# MSP430FR5962 register map
File version: 2.1
CPU: MSP430FR5962 r2p1, little endian, MPU, no FPU, 3 interrupt priority bits
Registers are 16-bit, read-write, reset 0x0 unless marked. A register's access mark holds for its fields unless they carry their own. Offsets are from the block's base; [hi:lo] are bit positions; 'fields as' and 'values as' point back to an identical list.

## RAMCTL
Base 0x00000158
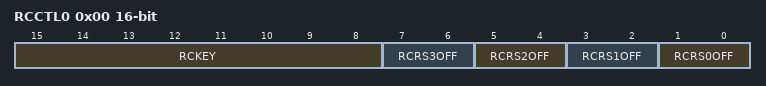
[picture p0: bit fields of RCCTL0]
0x00 RCCTL0 — RAM Controller Control 0
  [15:8] RCKEY — [15:8] RAM controller key. Always reads as 69h. Must be written as 5Ah; any other write is is ignored.
  [7:6] RCRS3OFF — [7:6] RAM controller RAM sector 3 off
    0=RCRS0OFF_0 (Contents of this RAM sector are retained in LPM3 and LPM4.); 1=RCRS0OFF_1 (Turns off this RAM sector in LPM3 and LPM4, re-activates it on wake-up. All data of this RAM sector is lost after wakeup from LPM3 and LPM4. See the device-specific data sheet to find the number of available sectors, the address range, and the size of each RAM sector.); 2=RCRS0OFF_2 (Turns off this RAM sector entering LPM3 and LPM4, the RAM sector remains off after wake-up. All data of this RAM sector is lost. See the devicespecific data sheet to find the number of available sectors, the address range, and the size of each RAM sector.)
  [5:4] RCRS2OFF — [5:4] RAM controller RAM sector 0 off
    values as RCRS3OFF
  [3:2] RCRS1OFF — [3:2] RAM controller RAM sector 0 off
    values as RCRS3OFF
  [1:0] RCRS0OFF — [1:0] RAM controller RAM sector 0 off
    0=Contents of this RAM sector are retained in LPM3 and LPM4; 1=Turns off this RAM sector in LPM3 and LPM4, re-activates it on wake-up. All data of this RAM sector is lost after wakeup from LPM3 and LPM4. See the device-specific data sheet to find the number of available sectors, the address range, and the size of each RAM sector.; 2=Turns off this RAM sector entering LPM3 and LPM4, the RAM sector remains off after wake-up. All data of this RAM sector is lost. See the devicespecific data sheet to find the number of available sectors, the address range, and the size of each RAM sector.

## REF_A
Base 0x000001B0
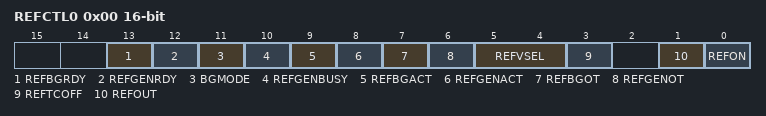
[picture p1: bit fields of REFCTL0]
0x00 REFCTL0 — REF Control Register 0
  [13] REFBGRDY — [13:13] Buffered bandgap voltage ready status
    0=Buffered bandgap voltage is not ready to be used; 1=Buffered bandgap voltage is ready to be used
  [12] REFGENRDY — [12:12] Variable reference voltage ready status
    0=Reference voltage output is not ready to be used; 1=Reference voltage output is ready to be used
  [11] BGMODE — [11:11] Bandgap mode
    0=Static mode; 1=Sampled mode
  [10] REFGENBUSY — [10:10] Reference generator busy
    0=Reference generator not busy; 1=Reference generator busy
  [9] REFBGACT — [9:9] Reference bandgap active
    0=Reference bandgap buffer not active; 1=Reference bandgap buffer active
  [8] REFGENACT — [8:8] Reference generator active
    0=Reference generator not active; 1=Reference generator active
  [7] REFBGOT — [7:7] Bandgap and bandgap buffer one-time trigger
    0=No trigger; 1=Generation of the bandgap voltage is started by writing 1 or by a hardware trigger
  [6] REFGENOT — [6:6] Reference generator one-time trigger
    0=No trigger; 1=Generation of the reference voltage is started by writing 1 or by a hardware trigger
  [5:4] REFVSEL — [5:4] Reference voltage level select
    0=1.2 V available when reference requested or REFON = 1; 1=2.0 V available when reference requested or REFON = 1; 2=2.5 V available when reference requested or REFON = 1; 3=2.5 V available when reference requested or REFON = 1
  [3] REFTCOFF — [3:3] Temperature sensor disabled
    0=Temperature sensor enabled; 1=Temperature sensor disabled to save power
  [1] REFOUT — [1:1] Reference output buffer
    0=Reference output not available externally; 1=Reference output available externally. If ADC14REFBURST = 0, output is available continuously. If ADC14REFBURST = 1, output is available only during an ADC14 conversion.
  [0] REFON — [0:0] Reference enable
    0=Disables reference if no other reference requests are pending; 1=Enables reference in static mode
